VERSION ""

NS_ :

BS_: 500000

BU_: GpsModule PowerControlModule EightButtonPanel BtGateway ShuntGateway MpptCanGateway TempSensor Borealis CanEspNowGateway PiCanToMqtt SevenPinTrailerMonitor ElectricHeaterControl VehicleLeveler Picket Switchback

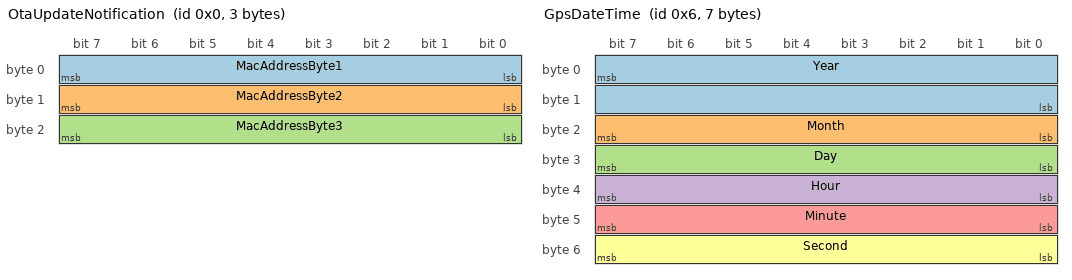
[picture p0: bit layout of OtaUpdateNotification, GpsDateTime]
BO_ 0 OtaUpdateNotification: 3 PiCanToMqtt
 SG_ MacAddressByte1 : 7|8@0+ (1,0) [0|255] "" Borealis,ElectricHeaterControl,VehicleLeveler,SevenPinTrailerMonitor,Picket,Switchback
 SG_ MacAddressByte2 : 15|8@0+ (1,0) [0|255] "" Borealis,ElectricHeaterControl,VehicleLeveler,SevenPinTrailerMonitor,Picket,Switchback
 SG_ MacAddressByte3 : 23|8@0+ (1,0) [0|255] "" Borealis,ElectricHeaterControl,VehicleLeveler,SevenPinTrailerMonitor,Picket,Switchback

BO_ 6 GpsDateTime: 7 GpsModule
 SG_ Year : 7|16@0+ (1,0) [2000|2099] "year" BtGateway,CanEspNowGateway,PiCanToMqtt
 SG_ Month : 23|8@0+ (1,0) [1|12] "month" BtGateway,CanEspNowGateway,PiCanToMqtt
 SG_ Day : 31|8@0+ (1,0) [1|31] "day" BtGateway,CanEspNowGateway,PiCanToMqtt
 SG_ Hour : 39|8@0+ (1,0) [0|23] "hour" BtGateway,CanEspNowGateway,PiCanToMqtt
 SG_ Minute : 47|8@0+ (1,0) [0|59] "min" BtGateway,CanEspNowGateway,PiCanToMqtt
 SG_ Second : 55|8@0+ (1,0) [0|59] "sec" BtGateway,CanEspNowGateway,PiCanToMqtt

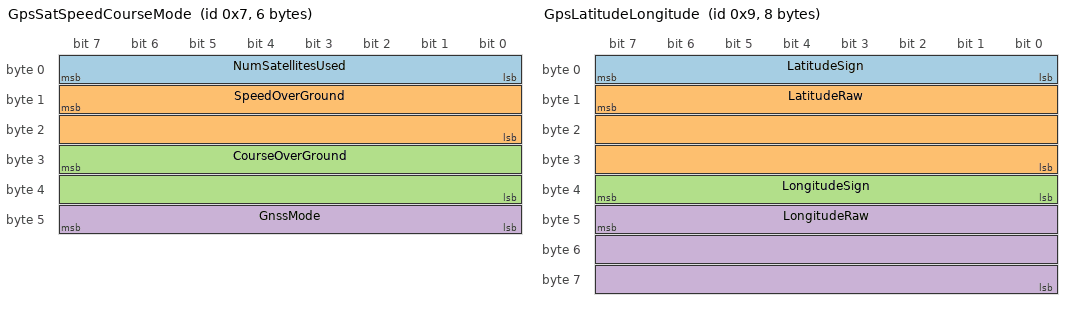
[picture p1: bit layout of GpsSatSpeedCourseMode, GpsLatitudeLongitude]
BO_ 7 GpsSatSpeedCourseMode: 6 GpsModule
 SG_ NumSatellitesUsed : 7|8@0+ (1,0) [0|255] "satellites" BtGateway,CanEspNowGateway,PiCanToMqtt
 SG_ SpeedOverGround : 15|16@0+ (0.01,0) [0|655.35] "knots" BtGateway,CanEspNowGateway,PiCanToMqtt
 SG_ CourseOverGround : 31|16@0+ (0.1,0) [0|6553.5] "deg" BtGateway,CanEspNowGateway,PiCanToMqtt
 SG_ GnssMode : 47|8@0+ (1,0) [0|255] "" BtGateway,CanEspNowGateway,PiCanToMqtt

BO_ 8 GpsAltitude: 4 GpsModule
 SG_ Altitude : 7|32@0+ (0.01,0) [0|42949672.95] "m" BtGateway,CanEspNowGateway,PiCanToMqtt

BO_ 9 GpsLatitudeLongitude: 8 GpsModule
 SG_ LatitudeSign : 7|8@0+ (1,0) [0|1] "" BtGateway,CanEspNowGateway,PiCanToMqtt
 SG_ LatitudeRaw : 15|24@0+ (0.0001,0) [0|1677.7215] "deg" BtGateway,CanEspNowGateway,PiCanToMqtt
 SG_ LongitudeSign : 39|8@0+ (1,0) [0|1] "" BtGateway,CanEspNowGateway,PiCanToMqtt
 SG_ LongitudeRaw : 47|24@0+ (0.0001,0) [0|1677.7215] "deg" BtGateway,CanEspNowGateway,PiCanToMqtt

BO_ 10 PicketStatus0: 2 Picket
 SG_ DoorStatus1to8 : 7|8@0+ (1,0) [0|255] "" BtGateway,CanEspNowGateway,PiCanToMqtt
 SG_ DoorStatus9to10 : 15|8@0+ (1,0) [0|3] "" BtGateway,CanEspNowGateway,PiCanToMqtt

BO_ 11 PicketStatus1: 2 Picket
 SG_ DoorStatus1to8 : 7|8@0+ (1,0) [0|255] "" BtGateway,CanEspNowGateway,PiCanToMqtt
 SG_ DoorStatus9to10 : 15|8@0+ (1,0) [0|3] "" BtGateway,CanEspNowGateway,PiCanToMqtt

BO_ 12 PicketStatus2: 2 Picket
 SG_ DoorStatus1to8 : 7|8@0+ (1,0) [0|255] "" BtGateway,CanEspNowGateway,PiCanToMqtt
 SG_ DoorStatus9to10 : 15|8@0+ (1,0) [0|3] "" BtGateway,CanEspNowGateway,PiCanToMqtt

BO_ 13 PicketStatus3: 2 Picket
 SG_ DoorStatus1to8 : 7|8@0+ (1,0) [0|255] "" BtGateway,CanEspNowGateway,PiCanToMqtt
 SG_ DoorStatus9to10 : 15|8@0+ (1,0) [0|3] "" BtGateway,CanEspNowGateway,PiCanToMqtt

BO_ 14 PicketStatus4: 2 Picket
 SG_ DoorStatus1to8 : 7|8@0+ (1,0) [0|255] "" BtGateway,CanEspNowGateway,PiCanToMqtt
 SG_ DoorStatus9to10 : 15|8@0+ (1,0) [0|3] "" BtGateway,CanEspNowGateway,PiCanToMqtt

BO_ 15 PicketStatus5: 2 Picket
 SG_ DoorStatus1to8 : 7|8@0+ (1,0) [0|255] "" BtGateway,CanEspNowGateway,PiCanToMqtt
 SG_ DoorStatus9to10 : 15|8@0+ (1,0) [0|3] "" BtGateway,CanEspNowGateway,PiCanToMqtt

BO_ 16 PicketStatus6: 2 Picket
 SG_ DoorStatus1to8 : 7|8@0+ (1,0) [0|255] "" BtGateway,CanEspNowGateway,PiCanToMqtt
 SG_ DoorStatus9to10 : 15|8@0+ (1,0) [0|3] "" BtGateway,CanEspNowGateway,PiCanToMqtt

BO_ 17 PicketStatus7: 2 Picket
 SG_ DoorStatus1to8 : 7|8@0+ (1,0) [0|255] "" BtGateway,CanEspNowGateway,PiCanToMqtt
 SG_ DoorStatus9to10 : 15|8@0+ (1,0) [0|3] "" BtGateway,CanEspNowGateway,PiCanToMqtt

BO_ 21 BrightnessControl: 2 BtGateway
 SG_ ChannelIndex : 7|8@0+ (1,0) [0|7] "" PowerControlModule
 SG_ BrightnessLevel : 15|8@0+ (1,0) [0|255] "" PowerControlModule

BO_ 24 ToggleOnOffCommand: 2 EightButtonPanel
 SG_ ButtonOrCommand : 7|8@0+ (1,0) [0|9] "" PowerControlModule
 SG_ CommandValue : 15|8@0+ (1,0) [0|255] "" PowerControlModule

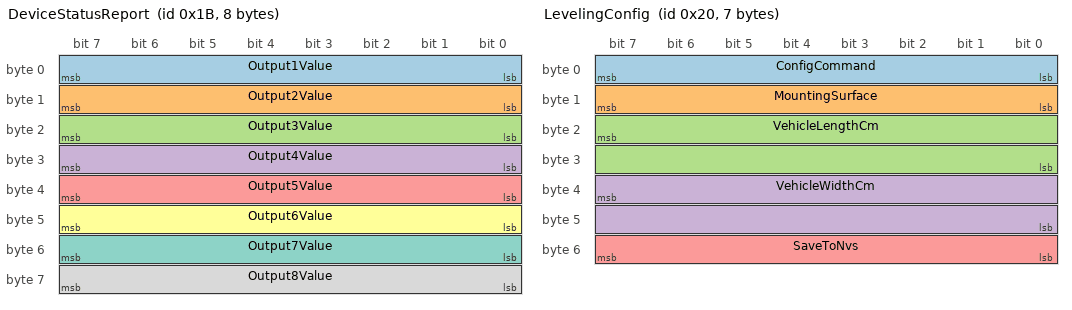
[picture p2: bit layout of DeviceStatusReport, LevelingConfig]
BO_ 27 DeviceStatusReport: 8 PowerControlModule
 SG_ Output1Value : 7|8@0+ (1,0) [0|255] "" BtGateway,EightButtonPanel,CanEspNowGateway,PiCanToMqtt
 SG_ Output2Value : 15|8@0+ (1,0) [0|255] "" BtGateway,EightButtonPanel,CanEspNowGateway,PiCanToMqtt
 SG_ Output3Value : 23|8@0+ (1,0) [0|255] "" BtGateway,EightButtonPanel,CanEspNowGateway,PiCanToMqtt
 SG_ Output4Value : 31|8@0+ (1,0) [0|255] "" BtGateway,EightButtonPanel,CanEspNowGateway,PiCanToMqtt
 SG_ Output5Value : 39|8@0+ (1,0) [0|255] "" BtGateway,EightButtonPanel,CanEspNowGateway,PiCanToMqtt
 SG_ Output6Value : 47|8@0+ (1,0) [0|255] "" BtGateway,EightButtonPanel,CanEspNowGateway,PiCanToMqtt
 SG_ Output7Value : 55|8@0+ (1,0) [0|255] "" BtGateway,EightButtonPanel,CanEspNowGateway,PiCanToMqtt
 SG_ Output8Value : 63|8@0+ (1,0) [0|255] "" BtGateway,EightButtonPanel,CanEspNowGateway,PiCanToMqtt

BO_ 30 LightSequenceCommand: 1 BtGateway
 SG_ SequenceType : 7|8@0+ (1,0) [0|1] "" PowerControlModule

BO_ 32 LevelingConfig: 7 PiCanToMqtt
 SG_ ConfigCommand : 7|8@0+ (1,0) [0|3] "" VehicleLeveler
 SG_ MountingSurface : 15|8@0+ (1,0) [0|2] "" VehicleLeveler
 SG_ VehicleLengthCm : 23|16@0+ (1,0) [0|65535] "cm" VehicleLeveler
 SG_ VehicleWidthCm : 39|16@0+ (1,0) [0|65535] "cm" VehicleLeveler
 SG_ SaveToNvs : 55|8@0+ (1,0) [0|1] "" VehicleLeveler

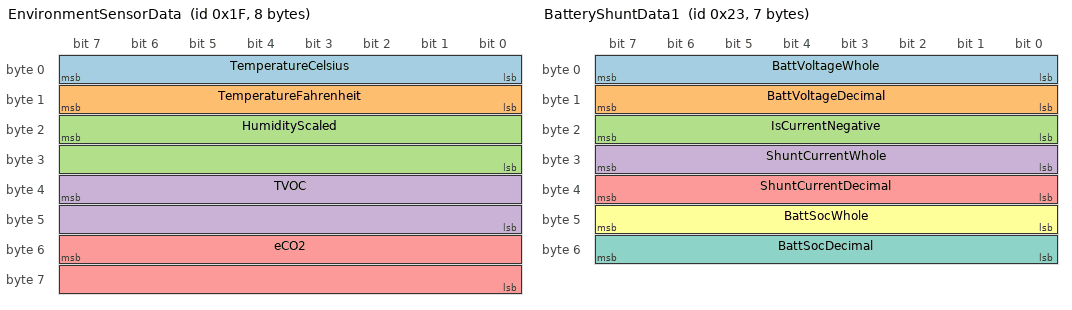
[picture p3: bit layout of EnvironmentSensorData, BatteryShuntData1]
BO_ 31 EnvironmentSensorData: 8 Borealis
 SG_ TemperatureCelsius : 7|8@0+ (1,0) [-40|125] "degC" BtGateway,CanEspNowGateway,PiCanToMqtt
 SG_ TemperatureFahrenheit : 15|8@0+ (1,0) [-40|257] "degF" BtGateway,CanEspNowGateway,PiCanToMqtt
 SG_ HumidityScaled : 23|16@0+ (0.01,0) [0|100] "%" BtGateway,CanEspNowGateway,PiCanToMqtt
 SG_ TVOC : 39|16@0+ (1,0) [0|60000] "ppb" BtGateway,CanEspNowGateway,PiCanToMqtt
 SG_ eCO2 : 55|16@0+ (1,0) [400|60000] "ppm" BtGateway,CanEspNowGateway,PiCanToMqtt

BO_ 35 BatteryShuntData1: 7 ShuntGateway
 SG_ BattVoltageWhole : 7|8@0+ (1,0) [0|255] "V" BtGateway,CanEspNowGateway,PiCanToMqtt
 SG_ BattVoltageDecimal : 15|8@0+ (1,0) [0|99] "0.01V" BtGateway,CanEspNowGateway,PiCanToMqtt
 SG_ IsCurrentNegative : 23|8@0+ (1,0) [0|1] "" BtGateway,CanEspNowGateway,PiCanToMqtt
 SG_ ShuntCurrentWhole : 31|8@0+ (1,0) [0|255] "A" BtGateway,CanEspNowGateway,PiCanToMqtt
 SG_ ShuntCurrentDecimal : 39|8@0+ (1,0) [0|99] "0.01A" BtGateway,CanEspNowGateway,PiCanToMqtt
 SG_ BattSocWhole : 47|8@0+ (1,0) [0|100] "%" BtGateway,CanEspNowGateway,PiCanToMqtt
 SG_ BattSocDecimal : 55|8@0+ (1,0) [0|99] "0.01%" BtGateway,CanEspNowGateway,PiCanToMqtt

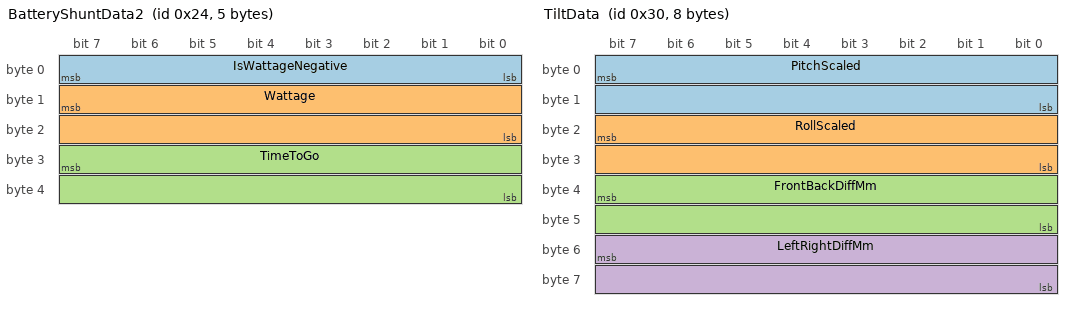
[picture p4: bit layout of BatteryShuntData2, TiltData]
BO_ 36 BatteryShuntData2: 5 ShuntGateway
 SG_ IsWattageNegative : 7|8@0+ (1,0) [0|255] "" BtGateway,CanEspNowGateway,PiCanToMqtt
 SG_ Wattage : 15|16@0+ (1,0) [0|65535] "W" BtGateway,CanEspNowGateway,PiCanToMqtt
 SG_ TimeToGo : 31|16@0+ (1,0) [0|65535] "min" BtGateway,CanEspNowGateway,PiCanToMqtt

BO_ 48 TiltData: 8 VehicleLeveler
 SG_ PitchScaled : 7|16@0- (0.01,0) [-327.68|327.67] "deg" BtGateway,CanEspNowGateway,PiCanToMqtt
 SG_ RollScaled : 23|16@0- (0.01,0) [-327.68|327.67] "deg" BtGateway,CanEspNowGateway,PiCanToMqtt
 SG_ FrontBackDiffMm : 39|16@0- (1,0) [-32768|32767] "mm" BtGateway,CanEspNowGateway,PiCanToMqtt
 SG_ LeftRightDiffMm : 55|16@0- (1,0) [-32768|32767] "mm" BtGateway,CanEspNowGateway,PiCanToMqtt

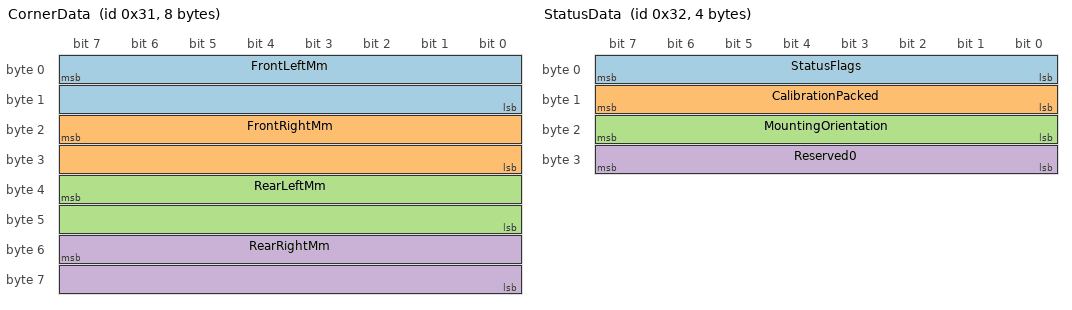
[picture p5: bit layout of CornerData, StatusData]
BO_ 49 CornerData: 8 VehicleLeveler
 SG_ FrontLeftMm : 7|16@0+ (1,0) [0|65535] "mm" BtGateway,CanEspNowGateway,PiCanToMqtt
 SG_ FrontRightMm : 23|16@0+ (1,0) [0|65535] "mm" BtGateway,CanEspNowGateway,PiCanToMqtt
 SG_ RearLeftMm : 39|16@0+ (1,0) [0|65535] "mm" BtGateway,CanEspNowGateway,PiCanToMqtt
 SG_ RearRightMm : 55|16@0+ (1,0) [0|65535] "mm" BtGateway,CanEspNowGateway,PiCanToMqtt

BO_ 50 StatusData: 4 VehicleLeveler
 SG_ StatusFlags : 7|8@0+ (1,0) [0|255] "" BtGateway,CanEspNowGateway,PiCanToMqtt
 SG_ CalibrationPacked : 15|8@0+ (1,0) [0|255] "" BtGateway,CanEspNowGateway,PiCanToMqtt
 SG_ MountingOrientation : 23|8@0+ (1,0) [0|2] "" BtGateway,CanEspNowGateway,PiCanToMqtt
 SG_ Reserved0 : 31|8@0+ (1,0) [0|0] "" BtGateway,CanEspNowGateway,PiCanToMqtt

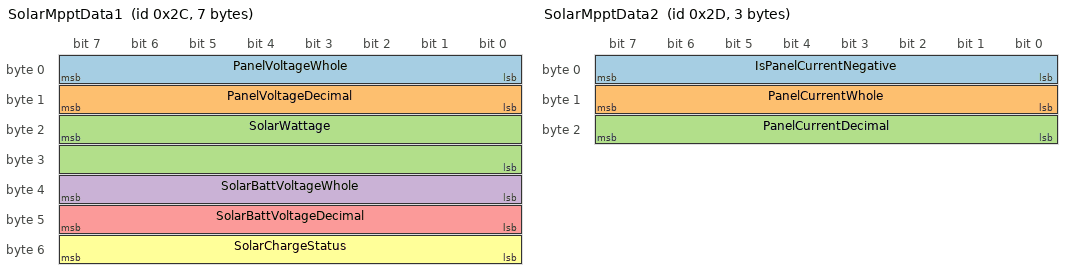
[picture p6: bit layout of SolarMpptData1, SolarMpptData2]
BO_ 44 SolarMpptData1: 7 MpptCanGateway
 SG_ PanelVoltageWhole : 7|8@0+ (1,0) [0|255] "V" BtGateway,CanEspNowGateway,PiCanToMqtt
 SG_ PanelVoltageDecimal : 15|8@0+ (1,0) [0|99] "0.01V" BtGateway,CanEspNowGateway,PiCanToMqtt
 SG_ SolarWattage : 23|16@0+ (1,0) [0|65535] "W" BtGateway,CanEspNowGateway,PiCanToMqtt
 SG_ SolarBattVoltageWhole : 39|8@0+ (1,0) [0|255] "V" BtGateway,CanEspNowGateway,PiCanToMqtt
 SG_ SolarBattVoltageDecimal : 47|8@0+ (1,0) [0|99] "0.01V" BtGateway,CanEspNowGateway,PiCanToMqtt
 SG_ SolarChargeStatus : 55|8@0+ (1,0) [0|255] "" BtGateway,CanEspNowGateway,PiCanToMqtt

BO_ 45 SolarMpptData2: 3 MpptCanGateway
 SG_ IsPanelCurrentNegative : 7|8@0+ (1,0) [0|1] "" BtGateway,CanEspNowGateway,PiCanToMqtt
 SG_ PanelCurrentWhole : 15|8@0+ (1,0) [0|255] "A" BtGateway,CanEspNowGateway,PiCanToMqtt
 SG_ PanelCurrentDecimal : 23|8@0+ (1,0) [0|99] "0.01A" BtGateway,CanEspNowGateway,PiCanToMqtt

BO_ 37 SwitchbackToggle0: 2 BtGateway
 SG_ RelayOrCommand : 7|8@0+ (1,0) [0|6] "" Switchback
 SG_ CommandValue : 15|8@0+ (1,0) [0|1] "" Switchback

BO_ 38 SwitchbackToggle1: 2 BtGateway
 SG_ RelayOrCommand : 7|8@0+ (1,0) [0|6] "" Switchback
 SG_ CommandValue : 15|8@0+ (1,0) [0|1] "" Switchback

BO_ 39 SwitchbackToggle2: 2 BtGateway
 SG_ RelayOrCommand : 7|8@0+ (1,0) [0|6] "" Switchback
 SG_ CommandValue : 15|8@0+ (1,0) [0|1] "" Switchback

BO_ 40 SwitchbackStatus0: 1 Switchback
 SG_ RelayStateBitmask : 7|8@0+ (1,0) [0|63] "" BtGateway,CanEspNowGateway,PiCanToMqtt

BO_ 41 SwitchbackStatus1: 1 Switchback
 SG_ RelayStateBitmask : 7|8@0+ (1,0) [0|63] "" BtGateway,CanEspNowGateway,PiCanToMqtt

BO_ 42 SwitchbackStatus2: 1 Switchback
 SG_ RelayStateBitmask : 7|8@0+ (1,0) [0|63] "" BtGateway,CanEspNowGateway,PiCanToMqtt

CM_ BU_ GpsModule "GPS receiver module (ESP32). Reads GNSS data from a connected GPS receiver and broadcasts position, altitude, speed, course, and date/time onto the CAN bus. Transmit-only device.";
CM_ BU_ PowerControlModule "8-channel PWM power distribution module (ESP32). Controls up to 8 MOSFET outputs for lights and accessories. Receives on/off toggle, brightness, and sequence commands. Sends status reports showing current state of all 8 outputs. Also known as the PDM (Power Distribution Module).";
CM_ BU_ EightButtonPanel "Physical 8-button panel (ESP32). Each button sends a toggle command to the Power Control Module to turn a corresponding output channel on or off. Has 8 status LEDs that reflect current output states by listening to DeviceStatusReport messages.";
CM_ BU_ BtGateway "Bluetooth Low Energy gateway (ESP32). Bridges the CAN bus to a smartphone app (Android). Receives sensor data and status from the CAN bus, converts it to BLE characteristic notifications. Also sends user commands from the phone app onto the CAN bus (toggles, brightness, sequences). Accepts ALL CAN messages.";
CM_ BU_ ShuntGateway "Battery shunt monitor gateway (ESP32). Reads Victron BMV battery monitor data via VE.Direct serial protocol (UART at 19200 baud) and converts it to CAN messages. Reports battery voltage, current draw, state of charge, wattage, and time-to-go. Transmit-only on CAN.";
CM_ BU_ MpptCanGateway "Solar charge controller gateway (ESP32). Reads Victron MPPT solar charge controller data via VE.Direct serial protocol (UART at 19200 baud) and converts it to CAN messages. Reports panel voltage, solar wattage, battery voltage, charge status, and panel current. Transmit-only on CAN.";
CM_ BU_ TempSensor "Temperature and humidity sensor module (ESP32). Reads a DHT22 sensor and broadcasts temperature (Celsius and Fahrenheit) and relative humidity onto the CAN bus. Uses the original canHelper approach with direct TWAI calls.";
CM_ BU_ Borealis "Environment and air quality sensor module (ESP32-S3-Zero). Reads DHT22 for temperature/humidity and SGP30 for TVOC/eCO2. Sends all data in a single 8-byte CAN frame at ID 0x1F. Bytes 0-3 are backwards-compatible with the predecessor AirQualityModule format. Bytes 4-7 add TVOC and eCO2 readings. Supports OTA firmware updates and WiFi credential provisioning via CAN. Uses TwaiTaskBased and OtaUpdate libraries.";
CM_ BU_ CanEspNowGateway "CAN-to-ESP-NOW bridge (ESP32). Listens to ALL messages on the CAN bus and forwards them wirelessly over ESP-NOW protocol to remote displays and controllers that are not physically wired to the CAN bus. Acts as a transparent CAN bus repeater over wireless.";
CM_ BU_ PiCanToMqtt "Raspberry Pi CAN-to-MQTT bridge. Runs a Python script that reads all CAN bus messages and publishes them as JSON over MQTT (with TLS). Also subscribes to MQTT and writes received commands back onto the CAN bus. Enables cloud connectivity and remote monitoring.";
CM_ BU_ SevenPinTrailerMonitor "Seven-pin trailer connector monitor (ESP32-C6). Monitors the standard 7-pin trailer connection for voltage, turn signals, brake signals, and running lights. Reports trailer connection state. Uses TwaiTaskBased library. Under active development.";
CM_ BU_ ElectricHeaterControl "Electric heater control module (ESP32-C6). Placeholder for controlling an electric heater. Uses TwaiTaskBased library. Listens for OTA update notifications on CAN. Under active development.";
CM_ BU_ VehicleLeveler "Vehicle leveling module (ESP32-S3-Zero with Adafruit BNO055 IMU). Reads pitch and roll from the BNO055 9-DOF IMU and computes per-corner height adjustments based on configurable vehicle dimensions. Supports three mounting orientations (floor, left wall, right wall) with automatic axis remapping. BNO055 calibration offsets are auto-saved to NVS when fully calibrated. Receives leveling configuration commands via CAN (ID 0x20). Transmits tilt data at 2Hz (ID 0x30), corner height data (ID 0x31), and calibration status every 2s (ID 0x32). Supports OTA firmware updates and WiFi credential provisioning via CAN. Uses TwaiTaskBased and OtaUpdate libraries.";
CM_ BU_ Picket "Picket module (ESP32-C6). Monitors up to 10 magnetic reed switch inputs to detect open/closed state of cabinet doors and enclosures. Uses a 3-position DIP switch to set a unique CAN address (0-7), allowing up to 8 modules on the same bus (CAN IDs 0x0A-0x11). A 4th DIP switch controls the 120 ohm CAN bus termination resistor. Uses TwaiTaskBased library. Supports OTA firmware updates via CAN.";
CM_ BU_ Switchback "6-channel relay control module (ESP32-S3, Waveshare ESP32-S3-Relay-6CH). Controls 6 mechanical relays for switching high-current loads. Receives toggle commands via CAN (ID 0x25-0x27, one per module instance). Sends relay status bitmask via CAN (ID 0x28-0x2A). Supports up to 3 modules on the same bus. Relays are binary on/off (not PWM). Supports OTA firmware updates and WiFi credential provisioning via CAN. Uses TwaiTaskBased and OtaUpdate libraries.";

CM_ BO_ 0 "OTA (Over-The-Air) firmware update notification. Sent by the Raspberry Pi when a new firmware build is available. Contains the last 3 bytes of the target device MAC address. Each device on the bus checks if the MAC matches its own hostname (formatted as esp32c6-XXYYZZ). If it matches, the device pauses normal operation, connects to WiFi, and checks for the OTA update. This allows targeted firmware updates to individual devices without disrupting others.";
CM_ BO_ 6 "GPS date and time data from the GNSS receiver. Sent periodically by the GPS Module. Year is encoded as a 16-bit unsigned integer split across bytes 0 and 1 (big-endian). Month, day, hour, minute, and second are each a single byte with their natural value. Time is in UTC.";
CM_ BO_ 7 "GPS navigation data: number of satellites being tracked, speed over ground, course over ground (heading), and the active GNSS constellation. Speed is in knots multiplied by 100 (divide raw value by 100 to get knots). Course is in degrees multiplied by 10 (divide raw value by 10 to get degrees, 0-360). GNSS mode indicates which satellite constellation combination is active (GPS, BeiDou, GLONASS, or combinations thereof).";
CM_ BO_ 8 "GPS altitude above mean sea level. Encoded as a 32-bit unsigned integer representing altitude in meters multiplied by 100 (divide raw value by 100 to get meters). For example, a raw value of 152340 means 1523.40 meters.";
CM_ BO_ 9 "GPS position: latitude and longitude. Each coordinate uses 4 bytes: a sign byte (0 = North/East positive, 1 = South/West negative) followed by a 24-bit unsigned integer representing the absolute value multiplied by 10000. To decode: take the 24-bit value, divide by 10000, and apply the sign. For example, sign=0 and raw=339876 means +33.9876 degrees.";
CM_ BO_ 10 "Picket status from module with DIP address 0 (all switches OFF). Sent at 5Hz. Each bit represents one reed switch input: 1 = door open (no magnet), 0 = door closed (magnet present). Byte 0 contains doors 1-8 (bit 0 = door 1 LSB, bit 7 = door 8 MSB). Byte 1 bits 0-1 contain doors 9-10, bits 2-7 are reserved. CAN IDs 0x0A through 0x11 share this identical signal layout, each sent by a different physical module selected via DIP switch address 0-7.";
CM_ BO_ 11 "Picket status from module with DIP address 1. Same signal layout as PicketStatus0 (ID 0x0A). See that message for full signal description.";
CM_ BO_ 12 "Picket status from module with DIP address 2. Same signal layout as PicketStatus0 (ID 0x0A).";
CM_ BO_ 13 "Picket status from module with DIP address 3. Same signal layout as PicketStatus0 (ID 0x0A).";
CM_ BO_ 14 "Picket status from module with DIP address 4. Same signal layout as PicketStatus0 (ID 0x0A).";
CM_ BO_ 15 "Picket status from module with DIP address 5. Same signal layout as PicketStatus0 (ID 0x0A).";
CM_ BO_ 16 "Picket status from module with DIP address 6. Same signal layout as PicketStatus0 (ID 0x0A).";
CM_ BO_ 17 "Picket status from module with DIP address 7 (all address switches ON). Same signal layout as PicketStatus0 (ID 0x0A).";
CM_ BO_ 21 "Brightness control command for the Power Control Module. Sets a specific PWM brightness level (0-255) for one of the 8 output channels. Byte 0 selects the channel (0-7), byte 1 sets the brightness level. A value of 0 turns the channel fully off, 255 is full brightness. Sent from the BtGateway (originating from the phone app) or from the PiCanToMqtt bridge.";
CM_ BO_ 24 "Toggle on/off command for the Power Control Module. Sent by the EightButtonPanel (physical buttons) or BtGateway (phone app). Byte 0 indicates which action: values 0-7 toggle the corresponding output channel on or off (if on turns off, if off turns on). Value 8 with byte 1 = 0 turns ALL outputs off, value 8 with byte 1 = 1 turns ALL outputs on. Value 9 with byte 1 = 1 turns ALL outputs on (similar to command 8 with value 1).";
CM_ BO_ 27 "Device status report from the Power Control Module. Sent continuously at ~30Hz. Each of the 8 data bytes represents the current PWM value (0 = off, 255 = full on) of the corresponding output channel. Used by the EightButtonPanel to update its status LEDs, by the BtGateway to update the phone app display, and by the CanEspNowGateway to relay to wireless displays.";
CM_ BO_ 30 "Light sequence animation command for the Power Control Module. Triggers a pre-programmed light show effect. Byte 0 value 0 starts the interior sequence (smooth fade in/out followed by a chase pattern on outputs 5-8). Byte 0 value 1 starts the exterior sequence (smooth fade in/out followed by an alternating flash on outputs 3-4). Sequences run to completion before normal control resumes.";
CM_ BO_ 31 "Environment sensor data. Sent by the Borealis module (replaces TempSensor/AirQualityModule). Bytes 0-3 are backwards-compatible: byte 0 is temperature in whole degrees Celsius, byte 1 is temperature in whole degrees Fahrenheit (F = (C * 9 + 3) / 5 + 32), bytes 2-3 are a 16-bit big-endian humidity value multiplied by 100. Bytes 4-5 are TVOC in ppb (16-bit big-endian, 0-60000). Bytes 6-7 are eCO2 in ppm (16-bit big-endian, 400-60000). TVOC and eCO2 read from an SGP30 sensor. The SGP30 needs ~15 seconds warm-up; initial values are TVOC=0, eCO2=400.";
CM_ BO_ 35 "Battery shunt monitor data part 1, from the Victron BMV battery monitor. Reports core battery metrics. Battery voltage is split into whole number (byte 0) and decimal part (byte 1) - combine as: voltage = byte0 + byte1/100. Byte 2 indicates if current is flowing out of the battery (1 = discharging/negative, 0 = charging/positive). Current is split similarly into whole (byte 3) and decimal (byte 4). State of charge percentage is split into whole (byte 5) and decimal (byte 6). For example: bytes 13, 45, 1, 5, 30, 85, 50 means 13.45V, -5.30A discharge, 85.50% SOC.";
CM_ BO_ 36 "Battery shunt monitor data part 2, from the Victron BMV battery monitor. Byte 0 indicates if wattage is negative (0xFF = battery discharging/negative, 0x00 = charging/positive). Bytes 1-2 form a 16-bit big-endian unsigned value for the absolute wattage in whole watts. Bytes 3-4 form a 16-bit big-endian unsigned value for time-to-go in minutes (how long until the battery is empty at the current discharge rate). For example: bytes 0xFF, 0x01, 0x2C, 0x02, 0x58 means -300W discharge, 600 minutes remaining.";
CM_ BO_ 37 "Relay toggle command for Switchback module instance 0. Byte 0 values 0-5 toggle the corresponding relay channel (0=CH1 ... 5=CH6). Value 6 is an all-channels command: byte 1 = 0 turns all relays off, byte 1 = 1 turns all relays on. CAN IDs 0x25-0x27 share this identical signal layout, each targeting a different physical Switchback module.";
CM_ BO_ 38 "Relay toggle command for Switchback module instance 1. Same signal layout as SwitchbackToggle0 (ID 0x25).";
CM_ BO_ 39 "Relay toggle command for Switchback module instance 2. Same signal layout as SwitchbackToggle0 (ID 0x25).";
CM_ BO_ 40 "Relay status report from Switchback module instance 0. Sent immediately on state change (event-driven, not periodic). Byte 0 is a bitmask of relay states: bit 0 = CH1, bit 1 = CH2, ... bit 5 = CH6. Value 1 = relay ON (energized), 0 = relay OFF. Bits 6-7 are reserved. CAN IDs 0x28-0x2A share this identical signal layout, each sent by a different physical Switchback module.";
CM_ BO_ 41 "Relay status report from Switchback module instance 1. Same signal layout as SwitchbackStatus0 (ID 0x28).";
CM_ BO_ 42 "Relay status report from Switchback module instance 2. Same signal layout as SwitchbackStatus0 (ID 0x28).";
CM_ BO_ 32 "Leveling configuration command for the VehicleLeveler. Byte 0 is the command type: 0x01 = set configuration (bytes 1-6 contain mounting surface, vehicle length, vehicle width, and save flag), 0x02 = request immediate status report on ID 0x32, 0x03 = zero/tare calibration (reserved). For command 0x01: byte 1 is the mounting surface (0=floor, 1=left wall, 2=right wall), bytes 2-3 are vehicle length in cm (big-endian uint16), bytes 4-5 are vehicle width in cm (big-endian uint16), byte 6 = 0x01 to persist to NVS. Configuration is applied immediately (including axis remap) even without saving.";
CM_ BO_ 48 "Vehicle tilt and height difference data from the BNO055 IMU. Sent at 2Hz (500ms interval). Pitch and roll are in degrees multiplied by 100 as signed 16-bit big-endian integers (divide by 100 for degrees). Positive pitch = front tilted up. Positive roll = right side tilted up. Front-back and left-right height differences are in millimeters, computed from tilt angles and configured vehicle dimensions using: diff_mm = dimension_cm * 10 * tan(angle_rad).";
CM_ BO_ 49 "Per-corner height adjustment data. Derived from pitch/roll and vehicle dimensions. Values represent how much each corner needs to be raised to achieve level, normalized so the lowest corner = 0. All values are unsigned 16-bit big-endian in millimeters. Corners are: front-left, front-right, rear-left, rear-right.";
CM_ BO_ 50 "Vehicle leveling system status. Sent every 2 seconds. Byte 0 is a flags bitmask: bit 0 = IMU connected, bit 1 = fully calibrated (cal_sys==3), bit 2 = leveling active. Byte 1 is packed BNO055 calibration levels: bits 7-6 = system (0-3), bits 5-4 = gyro (0-3), bits 3-2 = accel (0-3), bits 1-0 = mag (0-3). Byte 2 is the current mounting surface enum (0=floor, 1=left wall, 2=right wall). Byte 3 is reserved.";
CM_ BO_ 44 "Solar MPPT charge controller data part 1, from the Victron MPPT solar charger. Panel voltage is split into whole (byte 0) and decimal (byte 1) - combine as: panelV = byte0 + byte1/100. Bytes 2-3 form a 16-bit big-endian value for solar power in watts. Battery voltage (as seen by the charger) is split into whole (byte 4) and decimal (byte 5). Byte 6 is the solar charge status enum from the Victron CS field (0 = Off, 2 = Fault, 3 = Bulk, 4 = Absorption, 5 = Float).";
CM_ BO_ 45 "Solar MPPT charge controller data part 2, from the Victron MPPT solar charger. Byte 0 indicates if panel current is negative (1 = yes, 0 = no). Panel current is split into whole number (byte 1) and decimal (byte 2) - combine as: current = byte1 + byte2/100 amps. Apply sign from byte 0.";

CM_ SG_ 0 MacAddressByte1 "First byte of the target device MAC address for OTA update. Combined with bytes 2 and 3, forms the hostname pattern esp32c6-XXYYZZ where XX is this byte in hex.";
CM_ SG_ 0 MacAddressByte2 "Second byte of the target device MAC address for OTA update.";
CM_ SG_ 0 MacAddressByte3 "Third byte of the target device MAC address for OTA update.";
CM_ SG_ 6 Year "Calendar year in UTC (e.g. 2025). Encoded as 16-bit big-endian unsigned integer.";
CM_ SG_ 6 Month "Month of year 1-12 in UTC.";
CM_ SG_ 6 Day "Day of month 1-31 in UTC.";
CM_ SG_ 6 Hour "Hour of day 0-23 in UTC.";
CM_ SG_ 6 Minute "Minute of hour 0-59 in UTC.";
CM_ SG_ 6 Second "Second of minute 0-59 in UTC.";
CM_ SG_ 7 NumSatellitesUsed "Number of GNSS satellites actively used for position calculation. More satellites generally means better accuracy.";
CM_ SG_ 7 SpeedOverGround "Speed over ground from GPS. Raw value on the bus is the actual speed in knots multiplied by 100. The factor of 0.01 in this DBC definition automatically converts to knots. For example, raw value 550 means 5.50 knots.";
CM_ SG_ 7 CourseOverGround "Course over ground (heading/bearing) from GPS in degrees. Raw value is degrees multiplied by 10. The factor of 0.1 converts automatically. 0 = North, 90 = East, 180 = South, 270 = West.";
CM_ SG_ 7 GnssMode "Active GNSS constellation combination from the DFRobot GNSS module. Indicates which satellite systems are being used for position calculation. Value 0 means no constellation is active. Values 1-7 represent different combinations of GPS, BeiDou, and GLONASS.";
CM_ SG_ 8 Altitude "Altitude above mean sea level in meters. Raw 32-bit value is meters multiplied by 100. The factor of 0.01 converts automatically. For example, raw value 152340 = 1523.40 meters.";
CM_ SG_ 9 LatitudeSign "Sign of latitude: 0 = positive (North), 1 = negative (South).";
CM_ SG_ 9 LatitudeRaw "Absolute value of latitude in degrees. Raw 24-bit value is degrees multiplied by 10000. The factor of 0.0001 converts automatically. Combine with LatitudeSign for the final value. Example: sign=0, raw=339876 means +33.9876 degrees North.";
CM_ SG_ 9 LongitudeSign "Sign of longitude: 0 = positive (East), 1 = negative (West).";
CM_ SG_ 9 LongitudeRaw "Absolute value of longitude in degrees. Raw 24-bit value is degrees multiplied by 10000. The factor of 0.0001 converts automatically. Combine with LongitudeSign for the final value.";
CM_ SG_ 10 DoorStatus1to8 "Bitmask of door/cabinet reed switch states for inputs 1-8. Each bit represents one input: bit 0 = door 1 (RSW01), bit 1 = door 2 (RSW02), ... bit 7 = door 8 (RSW08). Value 1 = door open (reed switch open, no magnet nearby). Value 0 = door closed (reed switch closed, magnet present). Applies identically to CAN IDs 0x0A through 0x11.";
CM_ SG_ 10 DoorStatus9to10 "Bitmask of door/cabinet reed switch states for inputs 9-10. Bit 0 = door 9 (RSW09), bit 1 = door 10 (RSW10). Bits 2-7 are reserved and always 0. Value 1 = door open, 0 = door closed. Applies identically to CAN IDs 0x0A through 0x11.";
CM_ SG_ 21 ChannelIndex "Output channel number to control (0-7). Channel 0 corresponds to Output 1, channel 7 to Output 8.";
CM_ SG_ 21 BrightnessLevel "PWM brightness level for the selected channel. 0 = fully off, 255 = fully on. Values in between produce proportional brightness via PWM.";
CM_ SG_ 24 ButtonOrCommand "Button index or special command code. Values 0-7: toggle the corresponding output channel (0=Output1 ... 7=Output8). Value 8: all-channels command (use CommandValue byte). Value 9: turn all channels on (when CommandValue=1).";
CM_ SG_ 24 CommandValue "Value parameter for special commands. When ButtonOrCommand=8: 0 = turn all off, 1 = turn all on. When ButtonOrCommand=9: 1 = turn all on. For single-channel toggles (0-7) this byte may not be present (DLC=1) or is ignored.";
CM_ SG_ 27 Output1Value "Current PWM brightness value of output channel 1. 0 = off, 255 = full on.";
CM_ SG_ 27 Output2Value "Current PWM brightness value of output channel 2. 0 = off, 255 = full on.";
CM_ SG_ 27 Output3Value "Current PWM brightness value of output channel 3. 0 = off, 255 = full on.";
CM_ SG_ 27 Output4Value "Current PWM brightness value of output channel 4. 0 = off, 255 = full on.";
CM_ SG_ 27 Output5Value "Current PWM brightness value of output channel 5. 0 = off, 255 = full on.";
CM_ SG_ 27 Output6Value "Current PWM brightness value of output channel 6. 0 = off, 255 = full on.";
CM_ SG_ 27 Output7Value "Current PWM brightness value of output channel 7. 0 = off, 255 = full on.";
CM_ SG_ 27 Output8Value "Current PWM brightness value of output channel 8. 0 = off, 255 = full on.";
CM_ SG_ 30 SequenceType "Light animation sequence to play. 0 = Interior sequence (fade + chase on outputs 5-8, good for interior ambient lighting effects). 1 = Exterior sequence (fade + alternating flash on outputs 3-4, good for exterior accent lighting).";
CM_ SG_ 31 TemperatureCelsius "Air temperature reading in whole degrees Celsius from the DHT22 sensor.";
CM_ SG_ 31 TemperatureFahrenheit "Air temperature reading in whole degrees Fahrenheit, converted from Celsius using: F = (C * 9 + 3) / 5 + 32.";
CM_ SG_ 31 HumidityScaled "Relative humidity percentage. Raw 16-bit value is humidity multiplied by 100. The factor of 0.01 converts automatically. For example, raw 5523 means 55.23% relative humidity.";
CM_ SG_ 31 TVOC "Total Volatile Organic Compounds in parts per billion from the SGP30 sensor. Range 0-60000 ppb. Air quality interpretation: 0-65 Excellent, 65-220 Good, 220-660 Moderate, 660-2200 Poor, 2200+ Unhealthy. Reads 0 during the ~15 second warm-up period.";
CM_ SG_ 31 eCO2 "Equivalent CO2 concentration in parts per million from the SGP30 sensor. Range 400-60000 ppm. Levels: <400 Low (fresh/outdoor air), 400-999 Normal (well-ventilated indoor), 1000-1999 High (poor ventilation), >=2000 Alarm (immediate ventilation needed). Reads 400 during warm-up.";
CM_ SG_ 32 ConfigCommand "Configuration command type. 0x01 = set vehicle config (use remaining bytes). 0x02 = request immediate status report on CAN ID 0x32. 0x03 = zero/tare calibration reset (reserved for future use).";
CM_ SG_ 32 MountingSurface "Mounting orientation of the IMU on the vehicle. 0 = floor (horizontal, default), 1 = left wall (vertical, left side), 2 = right wall (vertical, right side). Determines BNO055 axis remapping for correct pitch/roll interpretation.";
CM_ SG_ 32 VehicleLengthCm "Vehicle length in centimeters, front axle to rear axle. 16-bit big-endian unsigned. Used to compute front-to-back height difference from pitch angle. Default 500 (5 meters).";
CM_ SG_ 32 VehicleWidthCm "Vehicle width in centimeters, left wheel to right wheel. 16-bit big-endian unsigned. Used to compute left-to-right height difference from roll angle. Default 200 (2 meters).";
CM_ SG_ 32 SaveToNvs "Set to 0x01 to persist the configuration to NVS flash so it survives reboot. Set to 0x00 for temporary (session-only) configuration change.";
CM_ SG_ 48 PitchScaled "Vehicle pitch angle in degrees, multiplied by 100. Signed 16-bit big-endian. Divide by 100 for degrees. Positive = front tilted up relative to rear.";
CM_ SG_ 48 RollScaled "Vehicle roll angle in degrees, multiplied by 100. Signed 16-bit big-endian. Divide by 100 for degrees. Positive = right side tilted up relative to left.";
CM_ SG_ 48 FrontBackDiffMm "Height difference front-to-back in millimeters. Signed 16-bit big-endian. Positive = front is higher than rear. Computed as vehicle_length_cm * 10 * tan(pitch_rad).";
CM_ SG_ 48 LeftRightDiffMm "Height difference left-to-right in millimeters. Signed 16-bit big-endian. Positive = right side is higher than left. Computed as vehicle_width_cm * 10 * tan(roll_rad).";
CM_ SG_ 49 FrontLeftMm "Front-left corner height adjustment in millimeters. Amount this corner needs to be raised to achieve level. Normalized so the lowest corner = 0.";
CM_ SG_ 49 FrontRightMm "Front-right corner height adjustment in millimeters. Normalized so the lowest corner = 0.";
CM_ SG_ 49 RearLeftMm "Rear-left corner height adjustment in millimeters. Normalized so the lowest corner = 0.";
CM_ SG_ 49 RearRightMm "Rear-right corner height adjustment in millimeters. Normalized so the lowest corner = 0.";
CM_ SG_ 50 StatusFlags "Bitmask of system status flags. Bit 0 (0x01): IMU connected and communicating. Bit 1 (0x02): BNO055 fully calibrated (system calibration level = 3). Bit 2 (0x04): leveling computation active.";
CM_ SG_ 50 CalibrationPacked "Packed BNO055 calibration status. Each field is 0-3 where 3 = fully calibrated. Bits 7-6: system cal. Bits 5-4: gyro cal. Bits 3-2: accelerometer cal. Bits 1-0: magnetometer cal.";
CM_ SG_ 50 MountingOrientation "Current mounting surface configuration. 0 = floor, 1 = left wall, 2 = right wall. Reflects the active axis remap mode.";
CM_ SG_ 50 Reserved0 "Reserved byte, always 0x00.";
CM_ SG_ 35 BattVoltageWhole "Battery voltage whole number part in volts. Combine with BattVoltageDecimal as: voltage = BattVoltageWhole + BattVoltageDecimal / 100.0 to get the full voltage reading.";
CM_ SG_ 35 BattVoltageDecimal "Battery voltage decimal part (hundredths of a volt, 0-99). See BattVoltageWhole for how to reconstruct the full voltage.";
CM_ SG_ 35 IsCurrentNegative "Indicates direction of current flow. 0 = positive/charging (current flowing into battery). 1 = negative/discharging (current flowing out of battery). Apply this sign to the current value from ShuntCurrentWhole + ShuntCurrentDecimal.";
CM_ SG_ 35 ShuntCurrentWhole "Battery current whole number part in amps. Combine with ShuntCurrentDecimal as: current = ShuntCurrentWhole + ShuntCurrentDecimal / 100.0, then apply sign from IsCurrentNegative.";
CM_ SG_ 35 ShuntCurrentDecimal "Battery current decimal part (hundredths of an amp, 0-99). See ShuntCurrentWhole for how to reconstruct the full current.";
CM_ SG_ 35 BattSocWhole "Battery state of charge whole number part (percentage). Combine with BattSocDecimal as: SOC = BattSocWhole + BattSocDecimal / 100.0 to get a value like 85.50%.";
CM_ SG_ 35 BattSocDecimal "Battery state of charge decimal part (hundredths of a percent, 0-99). See BattSocWhole for how to reconstruct the full SOC value.";
CM_ SG_ 36 IsWattageNegative "Indicates direction of power flow. 0x00 (0) = positive/charging. 0xFF (255) = negative/discharging. Note: uses 0xFF rather than 1 to indicate negative.";
CM_ SG_ 36 Wattage "Battery power consumption in whole watts. 16-bit big-endian unsigned value. Apply sign from IsWattageNegative. Positive means power flowing into battery (charging), negative means power drawn from battery (loads active).";
CM_ SG_ 36 TimeToGo "Estimated time remaining until battery is depleted at the current discharge rate, in minutes. 16-bit big-endian unsigned value. Value of 65535 may indicate infinite (battery is charging). Divide by 60 to get hours.";
CM_ SG_ 37 RelayOrCommand "Relay channel or special command code. Values 0-5: toggle the corresponding relay (0=CH1 ... 5=CH6). Value 6: all-channels command (use CommandValue byte). Applies identically to CAN IDs 0x25-0x27.";
CM_ SG_ 37 CommandValue "Value parameter for the all-channels command. When RelayOrCommand=6: 0 = turn all relays off, 1 = turn all relays on. Ignored for single-channel toggles (0-5).";
CM_ SG_ 40 RelayStateBitmask "Bitmask of current relay states. Bit 0 = CH1, bit 1 = CH2, bit 2 = CH3, bit 3 = CH4, bit 4 = CH5, bit 5 = CH6. Value 1 = relay ON (energized), 0 = relay OFF. Bits 6-7 are reserved and always 0. Applies identically to CAN IDs 0x28-0x2A.";
CM_ SG_ 44 PanelVoltageWhole "Solar panel voltage whole number part in volts. Combine with PanelVoltageDecimal as: panelV = PanelVoltageWhole + PanelVoltageDecimal / 100.0.";
CM_ SG_ 44 PanelVoltageDecimal "Solar panel voltage decimal part (hundredths of a volt, 0-99).";
CM_ SG_ 44 SolarWattage "Total solar power output in whole watts. 16-bit big-endian unsigned value. This is the instantaneous power being generated by the solar panels.";
CM_ SG_ 44 SolarBattVoltageWhole "Battery voltage as measured by the solar charge controller, whole number part in volts. May differ slightly from the shunt battery voltage due to different measurement points. Combine with SolarBattVoltageDecimal.";
CM_ SG_ 44 SolarBattVoltageDecimal "Battery voltage decimal part as measured by the solar charger (hundredths of a volt, 0-99).";
CM_ SG_ 44 SolarChargeStatus "Victron MPPT charge status enum (CS field). 0 = Off (charger disabled or no sunlight). 2 = Fault (error condition). 3 = Bulk charging (high current to quickly fill battery). 4 = Absorption (voltage held constant, current decreasing). 5 = Float (battery full, maintaining charge).";
CM_ SG_ 45 IsPanelCurrentNegative "Indicates if panel current is negative. 0 = positive (normal solar generation). 1 = negative (unusual, may indicate reverse current).";
CM_ SG_ 45 PanelCurrentWhole "Solar panel current whole number part in amps. Combine with PanelCurrentDecimal as: current = PanelCurrentWhole + PanelCurrentDecimal / 100.0, then apply sign from IsPanelCurrentNegative.";
CM_ SG_ 45 PanelCurrentDecimal "Solar panel current decimal part (hundredths of an amp, 0-99).";

BA_DEF_ BO_ "CycleTime" INT 0 10000;
BA_DEF_ "BusType" STRING;
BA_DEF_ "DatabaseVersion" STRING;
BA_DEF_ "ProtocolType" STRING;

BA_DEF_DEF_ "CycleTime" 0;
BA_DEF_DEF_ "BusType" "";
BA_DEF_DEF_ "DatabaseVersion" "";
BA_DEF_DEF_ "ProtocolType" "";

BA_ "BusType" "CAN";
BA_ "DatabaseVersion" "1.0.0";
BA_ "ProtocolType" "CAN 2.0A";

BA_ "CycleTime" BO_ 6 1000;
BA_ "CycleTime" BO_ 7 1000;
BA_ "CycleTime" BO_ 8 1000;
BA_ "CycleTime" BO_ 9 1000;
BA_ "CycleTime" BO_ 10 200;
BA_ "CycleTime" BO_ 11 200;
BA_ "CycleTime" BO_ 12 200;
BA_ "CycleTime" BO_ 13 200;
BA_ "CycleTime" BO_ 14 200;
BA_ "CycleTime" BO_ 15 200;
BA_ "CycleTime" BO_ 16 200;
BA_ "CycleTime" BO_ 17 200;
BA_ "CycleTime" BO_ 27 33;
BA_ "CycleTime" BO_ 48 500;
BA_ "CycleTime" BO_ 49 500;
BA_ "CycleTime" BO_ 50 2000;
BA_ "CycleTime" BO_ 31 2000;
BA_ "CycleTime" BO_ 35 33;
BA_ "CycleTime" BO_ 36 33;
BA_ "CycleTime" BO_ 44 33;
BA_ "CycleTime" BO_ 45 33;

VAL_ 9 LatitudeSign 0 "North_Positive" 1 "South_Negative";
VAL_ 9 LongitudeSign 0 "East_Positive" 1 "West_Negative";
VAL_ 24 ButtonOrCommand 0 "Toggle_Output1" 1 "Toggle_Output2" 2 "Toggle_Output3" 3 "Toggle_Output4" 4 "Toggle_Output5" 5 "Toggle_Output6" 6 "Toggle_Output7" 7 "Toggle_Output8" 8 "All_Channels_Command" 9 "All_Channels_On";
VAL_ 30 SequenceType 0 "Interior_FadeAndChase" 1 "Exterior_FadeAndFlash";
VAL_ 35 IsCurrentNegative 0 "Charging_Positive" 1 "Discharging_Negative";
VAL_ 36 IsWattageNegative 0 "Charging_Positive" 255 "Discharging_Negative";
VAL_ 44 SolarChargeStatus 0 "Off" 2 "Fault" 3 "Bulk_Charging" 4 "Absorption_Charging" 5 "Float_Charging";
VAL_ 45 IsPanelCurrentNegative 0 "Normal_Positive" 1 "Reverse_Negative";
VAL_ 32 ConfigCommand 1 "Set_Vehicle_Config" 2 "Request_Status" 3 "Zero_Tare";
VAL_ 32 MountingSurface 0 "Floor" 1 "Left_Wall" 2 "Right_Wall";
VAL_ 50 MountingOrientation 0 "Floor" 1 "Left_Wall" 2 "Right_Wall";
VAL_ 37 RelayOrCommand 0 "Toggle_Relay1" 1 "Toggle_Relay2" 2 "Toggle_Relay3" 3 "Toggle_Relay4" 4 "Toggle_Relay5" 5 "Toggle_Relay6" 6 "All_Relays_Command";
VAL_ 7 GnssMode 0 "No_Constellation" 1 "GPS" 2 "BeiDou" 3 "GPS_BeiDou" 4 "GLONASS" 5 "GPS_GLONASS" 6 "BeiDou_GLONASS" 7 "GPS_BeiDou_GLONASS";
